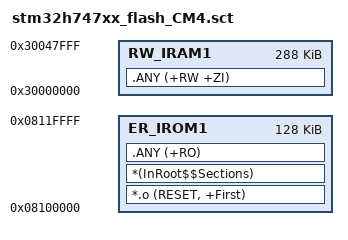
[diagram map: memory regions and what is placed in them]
; *************************************************************
; *** Scatter-Loading Description File for STM32H747 CM4 ***
; *************************************************************

; CM4 Flash 起始地址改为 CM7 结束的地方 (0x08000000 + 0x00100000)
LR_IROM1 0x08100000 0x00020000  {    ; CM4 只分配 128KB Flash
  ER_IROM1 0x08100000 0x00020000  {  
   *.o (RESET, +First)
   *(InRoot$$Sections)
   .ANY (+RO)
  }
  
  ; 修正：CM4 使用它独有的 288KB SRAM (RAM_D2)
  RW_IRAM1 0x30000000 0x00048000  {  
   .ANY (+RW +ZI)
  }
}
